# R7FA6M4AF register map
Vendor: Renesas Electronics Corporation; Series: RA6; File version: 1.20.04
CPU: CM33 r0p4, little endian, MPU, FPU, VTOR, 4 interrupt priority bits, 96 interrupts
Registers are 8-bit, read-write, reset 0x0 unless marked. A register's access mark holds for its fields unless they carry their own. Offsets are from the block's base; [hi:lo] are bit positions; {n}, {i} and the like mark numbered series; 'fields as' and 'values as' point back to an identical list.

## OSPI — Octa Serial Peripheral Interface
Base 0x400A6000
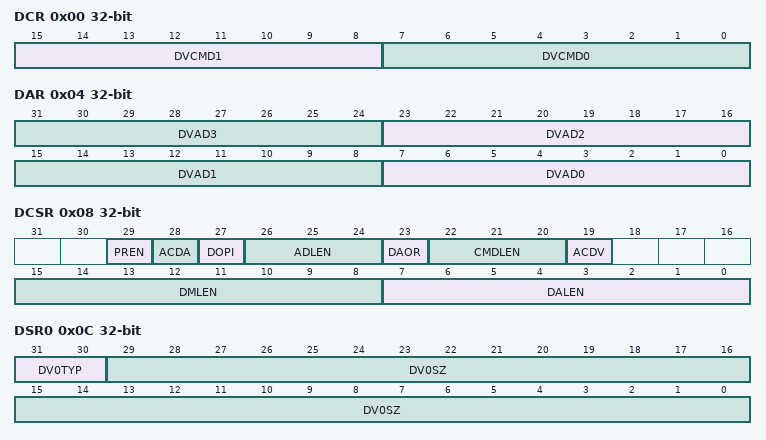
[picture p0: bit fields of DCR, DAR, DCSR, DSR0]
0x00 DCR 32-bit — Device Command Register
  [15:8] DVCMD1 — Device Command data
  [7:0] DVCMD0 — Device Command data
0x04 DAR 32-bit — Device Address Register
  [8n+7:8n] DVAD{n} (n=0..3) — Device Address data {n}
0x08 DCSR 32-bit — Device Command Setting Register
  [29] PREN — Preamble bit enable for OctaRAM
    0=No check preamble bit from OctaRAM; 1=Check preamble bit from OctaRAM
  [28] ACDA — Data Access Control
    0=Register access Do not arrange the transfer data; 1=Data access
  [27] DOPI — DOPI single byte setting
    0=Each cycle has two bytes data. (normal DOPI mode); 1=Each cycle has one byte data. (The byte data changes at the rising edge of the clock and does not change at the falling edge of the clock.)
  [26:24] ADLEN — Transfer address length setting
  [23] DAOR — Data order setting
    0=byte0, byte1, byte2, byte3; 1=byte1, byte0, byte3, byte2
  [22:20] CMDLEN — Transfer command length setting
  [19] ACDV — Access Device setting
    0=Send commands to device 0; 1=Send commands to device 1
  [15:8] DMLEN — Dummy cycle setting
  [7:0] DALEN — Transfer data length setting
0x0C DSR0 32-bit — Device Size Register 0
  [31:30] DV0TYP — Device 0 type setting
    0=Flash on device 0; 1=RAM on device 0; 2=No connection on device 0; 3=Forbidden
  [29:0] DV0SZ — Device 0 size setting
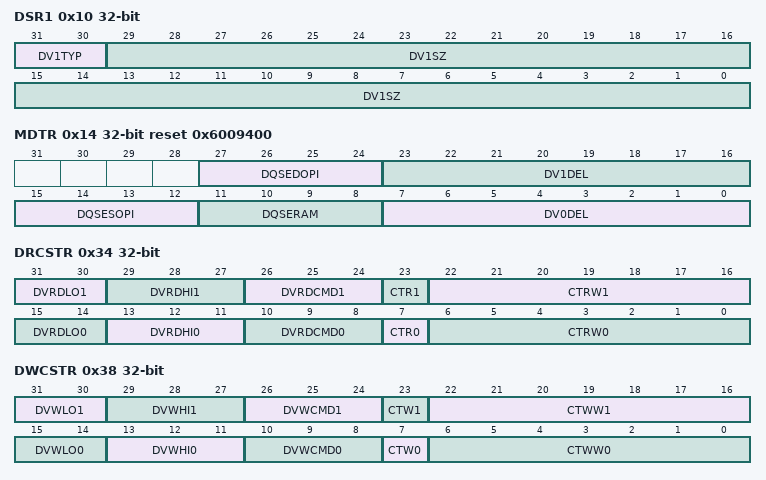
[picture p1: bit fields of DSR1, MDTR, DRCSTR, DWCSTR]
0x10 DSR1 32-bit — Device Size Register 1
  [31:30] DV1TYP — Device 1 type setting
    0=Flash on device 1; 1=RAM on device 1; 2=No connection on device 1; 3=Forbidden
  [29:0] DV1SZ — Device 1 size setting
0x14 MDTR 32-bit reset 0x6009400 — Memory Delay Trim Register
  [27:24] DQSEDOPI — OM_DQS enable counter
  [23:16] DV1DEL — Device 1 delay setting
  [15:12] DQSESOPI — OM_DQS enable counter
  [11:8] DQSERAM — OM_DQS enable counter
  [7:0] DV0DEL — Device 0 delay setting
0x18 ACTR 32-bit reset 0x10000000 — Auto-Calibration Timer Register
  [31:0] CTP — Automatic calibration cycle time setting
0x1C ACAR0 32-bit — Auto-Calibration Address Register 0
  [31:0] CAD0 — Automatic calibration address
0x20 ACAR1 32-bit — Auto-Calibration Address Register 1
  [31:0] CAD1 — Automatic calibration address
0x34 DRCSTR 32-bit — Device Memory Map Read Chip Select Timing Setting Register
  [31:30] DVRDLO1 — Device 1 select signal pull-down timing setting
    0=Setting prohibited; 1=2.5 clock cycles (DOPI mode) 3 clock cycles (Other mode); 2=3.5 clock cycles (DOPI mode) 4 clock cycles (Other mode); 3=4.5 clock cycles (DOPI mode) 5 clock cycles (Other mode)
  [29:27] DVRDHI1 — Device 1 select signal High timing setting
    0=Setting prohibit; 1=Setting prohibit; 2=Setting prohibit; 3=Setting prohibit (DOPI mode) 5 clock cycles (Other mode); 4=Setting prohibit (DOPI mode) 6 clock cycles (Other mode); 5=6.5 clock cycles (DOPI mode) 7 clock cycles (Other mode); 6=7.5 clock cycles (DOPI mode) 8 clock cycles (Other mode); 7=8.5 clock cycles (DOPI mode) 9 clock cycles (Other mode)
  [26:24] DVRDCMD1 — Device 1 Command execution interval
    0=2 clock cycles; 1=5 clock cycles; 2=7 clock cycles; 3=9 clock cycles; 4=11 clock cycles; 5=13 clock cycles; 6=15 clock cycles; 7=17 clock cycles
  [23] CTR1 — Device 1 single continuous read mode setting
    0=Single continuous read mode is disabled for device 1; 1=Single continuous read mode is enabled for device 1
  [22:16] CTRW1 — Device 1 single continuous read waiting cycle setting in PCLKA units
  [15:14] DVRDLO0 — Device 0 select signal pull-down timing setting
    0=Setting prohibit; 1=2.5 clock cycles (DOPI mode) 3 clock cycles (Other mode); 2=3.5 clock cycles (DOPI mode) 4 clock cycles (Other mode); 3=4.5 clock cycles (DOPI mode) 5 clock cycles (Other mode)
  [13:11] DVRDHI0 — Device 0 select signal pull-up timing setting
    values as DVRDHI1
  [10:8] DVRDCMD0 — Device 0 Command execution interval setting
    values as DVRDCMD1
  [7] CTR0 — Device 0 single continuous read mode setting
    0=Single continuous read mode is disabled for device 0; 1=Single continuous read mode is enabled for device 0
  [6:0] CTRW0 — Device 0 single continuous read waiting cycle setting in PCLKA units
0x38 DWCSTR 32-bit — Device Memory Map Write Chip Select Timing Setting Register
  [31:30] DVWLO1 — Device 1 select signal pull-down timing setting
    values as DRCSTR.DVRDLO0
  [29:27] DVWHI1 — Device 1 select signal pull-up timing setting
    0=1.5 clock cycles (DOPI mode) 2 clock cycles (Other mode); 1=2.5 clock cycles (DOPI mode) 3 clock cycles (Other mode); 2=3.5 clock cycles (DOPI mode) 4 clock cycles (Other mode); 3=4.5 clock cycles (DOPI mode) 5 clock cycles (Other mode); 4=5.5 clock cycles (DOPI mode) 6 clock cycles (Other mode); 5=6.5 clock cycles (DOPI mode) 7 clock cycles (Other mode); 6=7.5 clock cycles (DOPI mode) 8 clock cycles (Other mode); 7=8.5 clock cycles (DOPI mode) 9 clock cycles (Other mode)
  [26:24] DVWCMD1 — Device 1 Command execution interval setting
    0=setting prohibited; 1=5 clock cycles; 2=7 clock cycles; 3=9 clock cycles; 4=11 clock cycles; 5=13 clock cycles; 6=15 clock cycles; 7=17 clock cycles
  [23] CTW1 — Device 1 single continuous write mode setting
    0=Single continuous write mode is disabled for device 1; 1=Single continuous write mode is enabled for device 1
  [22:16] CTWW1 — Device 1 single continuous write waiting cycle setting in PCLKA units
  [15:14] DVWLO0 — Device 0 select signal pull-down timing setting
    values as DRCSTR.DVRDLO0
  [13:11] DVWHI0 — Device 0 select signal pull-up timing setting
    values as DVWHI1
  [10:8] DVWCMD0 — Device 0 Command execution interval setting
    values as DRCSTR.DVRDCMD1
  [7] CTW0 — Device 0 single continuous write mode setting
    0=Single continuous write mode is disabled for device 0; 1=Single continuous write mode is enabled for device 0
  [6:0] CTWW0 — Device 0 single continuous write waiting cycle setting in PCLKA units
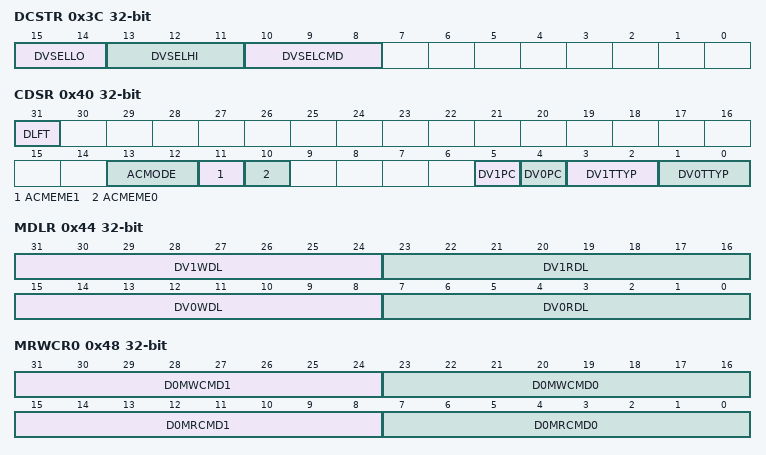
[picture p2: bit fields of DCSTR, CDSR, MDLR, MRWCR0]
0x3C DCSTR 32-bit — Device Chip Select Timing Setting Register
  [15:14] DVSELLO — Device select signal pull-down timing setting
    values as DRCSTR.DVRDLO0
  [13:11] DVSELHI — Device select signal pull-up timing setting
    0=Setting prohibited; 1=Setting prohibited; 2=Setting prohibited; 3=Setting prohibited (DOPI mode) 5 clock cycles (Other mode); 4=Setting prohibited (DOPI mode) 6 clock cycles (Other mode); 5=6.5 clock cycles (DOPI mode) 7 clock cycles (Other mode); 6=7.5 clock cycles (DOPI mode) 8 clock cycles (Other mode); 7=8.5 clock cycles (DOPI mode) 9 clock cycles (Other mode)
  [10:8] DVSELCMD — Device Command execution interval setting
    values as DRCSTR.DVRDCMD1
0x40 CDSR 32-bit — Controller and Device Setting Register
  [31] DLFT — Deadlock Free Timer Enable
    0=Enable timer; 1=Disable timer
  [13:12] ACMODE — Automatic calibration mode
    0=Automatic calibration is disabled; 1=Automatic calibration is enabled and modify MDTR; 2=Automatic calibration immediately is executed for all trim code, but it will not modify MDTR; 3=Setting prohibited
  [11] ACMEME1 — Automatic calibration memory enable setting for device 1
    0=Disable; 1=Enable
  [10] ACMEME0 — Automatic calibration memory enable setting for device 0
    0=Disable; 1=Enable
  [5] DV1PC — Device1_memory precycle setting
    0=Disable; 1=Enable
  [4] DV0PC — Device0_memory precycle setting
    0=Disable; 1=Enable
  [3:2] DV1TTYP — Device1_transfer_type setting
    0=SPI mode; 1=SOPI mode; 2=DOPI mode; 3=Setting prohibited
  [1:0] DV0TTYP — Device0_transfer_type setting
    0=SPI mode; 1=SOPI mode; 2=DOPI mode; 3=Setting prohibited
0x44 MDLR 32-bit — Memory Map Dummy Length Register
  [31:24] DV1WDL — Device 1 Write dummy length setting
  [23:16] DV1RDL — Device 1 Read dummy length setting
  [15:8] DV0WDL — Device 0 Write dummy length setting
  [7:0] DV0RDL — Device 0 Read dummy length setting
0x48 MRWCR0 32-bit — Memory Map Read/Write Command Register 0
  [31:24] D0MWCMD1 — Memory map write command 1 setting
  [23:16] D0MWCMD0 — Memory map write command 0 setting
  [15:8] D0MRCMD1 — Memory map read command 1 setting
  [7:0] D0MRCMD0 — Memory map read command 0 setting
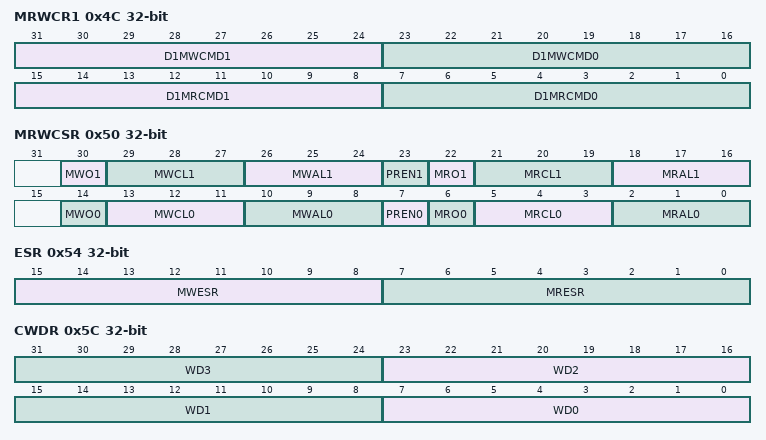
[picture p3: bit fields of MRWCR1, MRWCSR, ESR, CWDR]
0x4C MRWCR1 32-bit — Memory Map Read/Write Command Register 1
  [31:24] D1MWCMD1 — Memory map write command 1 setting
  [23:16] D1MWCMD0 — Memory map write command 0 setting
  [15:8] D1MRCMD1 — Memory map read command 1 setting
  [7:0] D1MRCMD0 — Memory map read command 0 setting
0x50 MRWCSR 32-bit — Memory Map Read/Write Setting Register
  [30] MWO1 — Device 1 write order setting
    0=Write order is byte0, byte1, byte2, byte3; 1=Write order is byte1, byte0, byte3, byte2
  [29:27] MWCL1 — Device 1 write command length setting
  [26:24] MWAL1 — Device 1 write address length setting
  [23] PREN1 — Preamble bit enable for mem1 memory-map read
    0=No check preamble bit; 1=Check preamble bit from OctaFlash (if OctaFlash is connected to device 1)
  [22] MRO1 — Device 1 read order setting
    0=Read order is byte0, byte1, byte2, byte3; 1=Read order is byte1, byte0, byte3, byte2
  [21:19] MRCL1 — Device 1 read command length setting
  [18:16] MRAL1 — Device 1 read address length setting
  [14] MWO0 — Device 0 write order setting
    values as MWO1
  [13:11] MWCL0 — Device 0 write command length setting
  [10:8] MWAL0 — Device 0 write address length setting
  [7] PREN0 — Preamble bit enable for mem0 memory-map read
    0=No check preamble bit; 1=Check preamble bit from OctaFlash (if OctaFlash is connected to device 0)
  [6] MRO0 — Device 0 read order setting
    values as MRO1
  [5:3] MRCL0 — Device 0 read command length setting
  [2:0] MRAL0 — Device 0 read address length setting
0x54 ESR 32-bit — Error Status Register
  [15:8] MWESR — Memory map write error status
    128=Invalid command; other=Others (Reserved)
  [7:0] MRESR — Memory map read error status
    1=ECC error; 2=Preamble error; 3=Wait OM_DQS timeout; 128=Invalid command; other=Others (Reserved)
0x58 CWNDR 32-bit wo — Configure Write without Data Register
  [31:0] WND — The write value should be 0.
0x5C CWDR 32-bit wo — Configure Write Data Register
  [8n+7:8n] WD{n} (n=0..3) — Write data {n}
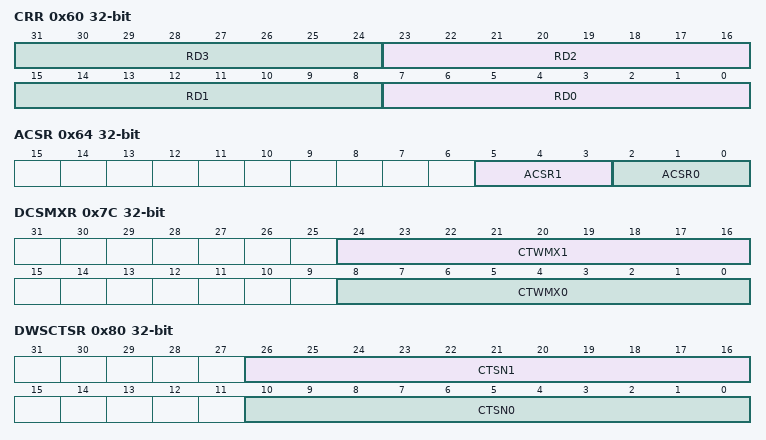
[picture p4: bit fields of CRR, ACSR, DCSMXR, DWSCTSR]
0x60 CRR 32-bit ro — Configure Read Register
  [8n+7:8n] RD{n} (n=0..3) — Read data {n}
0x64 ACSR 32-bit — Auto-Calibration Status Register
  [5:3] ACSR1 — Auto-calibration status of device 1
    0=Initial state; 3=Normal end; 4=Error end
  [2:0] ACSR0 — Auto-calibration status of device 0
    0=Initial state; 3=Normal end; 4=Error end
0x7C DCSMXR 32-bit — Device Chip Select Maximum Period Register
  [24:16] CTWMX1 — Indicates the maximum period that OM_CS0 and OM_CS1 are Low in single continuous read of OctaRAM.
  [8:0] CTWMX0 — Indicates the maximum period that OM_CS0 and OM_CS1 are Low in single continuous write of OctaRAM.
0x80 DWSCTSR 32-bit — Device Memory Map Write single continuous translating size Register
  [26:16] CTSN1 — Indicates the number of bytes to translate in single continuous write of device 1.
  [10:0] CTSN0 — Indicates the number of bytes to translate in single continuous write of device 0.
